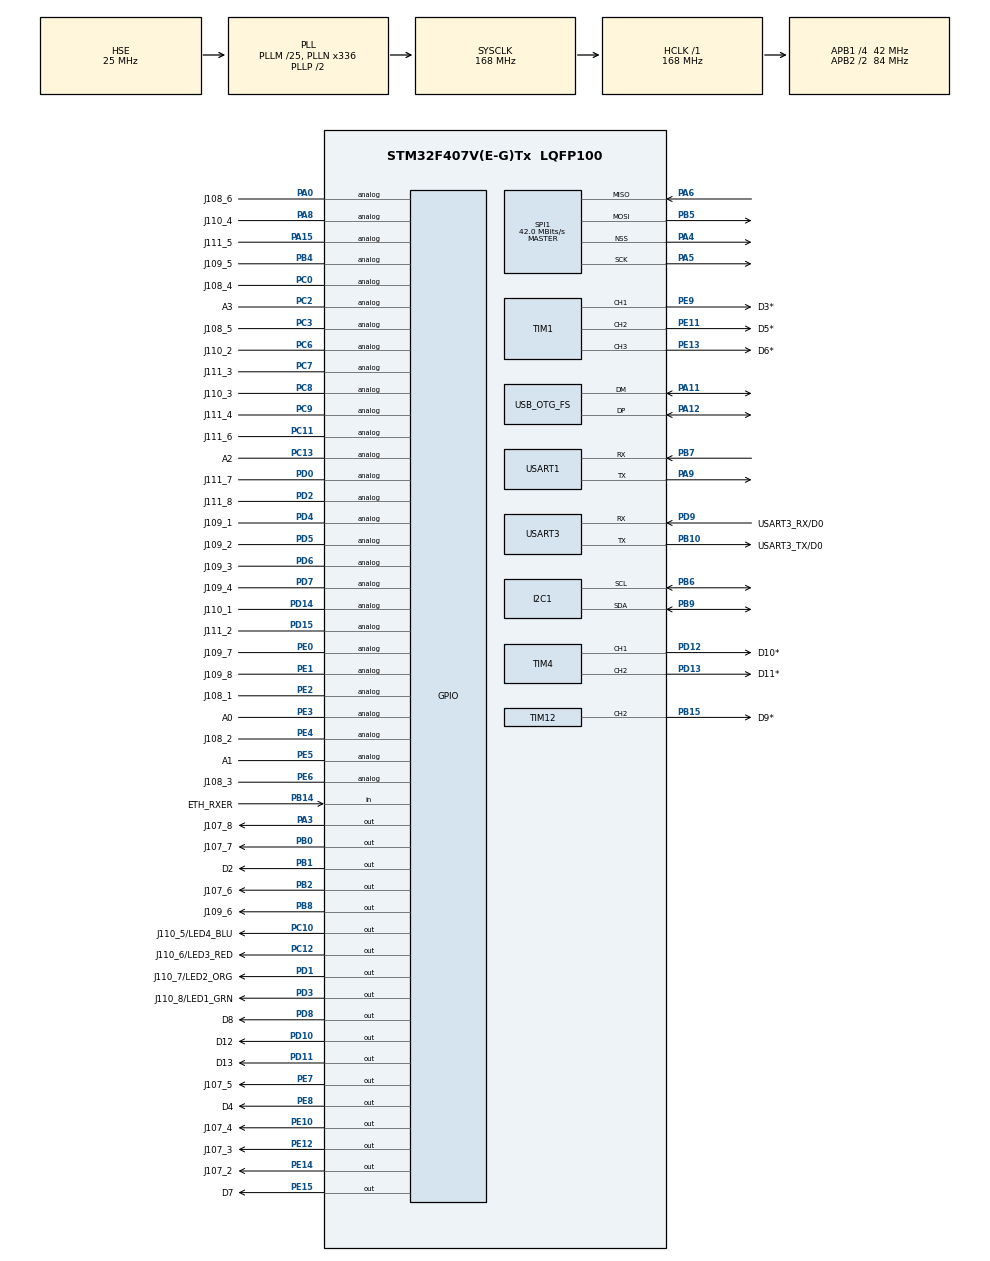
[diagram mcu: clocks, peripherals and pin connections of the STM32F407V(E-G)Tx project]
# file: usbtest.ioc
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Mcu.Family=STM32F4
Mcu.Name=STM32F407V(E-G)Tx
Mcu.Package=LQFP100
NVIC.OTG_FS_IRQn=true\:0\:0\:false\:false\:true\:false\:true\:true
NVIC.PriorityGroup=NVIC_PRIORITYGROUP_4
PA0-WKUP.GPIO_Label=J108_6
PA0-WKUP.Signal=GPIO_Analog
PA11.Mode=Device_Only
PA11.Signal=USB_OTG_FS_DM
PA12.Mode=Device_Only
PA12.Signal=USB_OTG_FS_DP
PA13.Mode=Trace_Asynchronous_SW
PA13.Signal=SYS_JTMS-SWDIO
PA14.Mode=Trace_Asynchronous_SW
PA14.Signal=SYS_JTCK-SWCLK
PA15.GPIO_Label=J111_5
PA15.Signal=GPIO_Analog
PA3.GPIO_Label=J107_8
PA3.Signal=GPIO_Output
PA4.Mode=NSS_Signal_Hard_Output
PA4.Signal=SPI1_NSS
PA5.Mode=Full_Duplex_Master
PA5.Signal=SPI1_SCK
PA6.Mode=Full_Duplex_Master
PA6.Signal=SPI1_MISO
PA8.GPIO_Label=J110_4
PA8.Signal=GPIO_Analog
PA9.Mode=Asynchronous
PA9.Signal=USART1_TX
PB0.GPIO_Label=J107_7
PB0.Signal=GPIO_Output
PB1.GPIO_Label=D2
PB1.Signal=GPIO_Output
PB10.GPIO_Label=USART3_TX/D0
PB10.Mode=Asynchronous
PB10.Signal=USART3_TX
PB14.GPIO_Label=ETH_RXER
PB14.Signal=GPIO_Input
PB15.GPIO_Label=D9*
PB15.Signal=S_TIM12_CH2
PB2.GPIO_Label=J107_6
PB2.Signal=GPIO_Output
PB3.Mode=Trace_Asynchronous_SW
PB3.Signal=SYS_JTDO-SWO
PB4.GPIO_Label=J109_5
PB4.Signal=GPIO_Analog
PB5.Mode=Full_Duplex_Master
PB5.Signal=SPI1_MOSI
PB6.Mode=I2C
PB6.Signal=I2C1_SCL
PB7.Mode=Asynchronous
PB7.Signal=USART1_RX
PB8.GPIO_Label=J109_6
PB8.Signal=GPIO_Output
PB9.Mode=I2C
PB9.Signal=I2C1_SDA
PC0.GPIO_Label=J108_4
PC0.Signal=GPIO_Analog
PC10.GPIO_Label=J110_5/LED4_BLU
PC10.Signal=GPIO_Output
PC11.GPIO_Label=J111_6
PC11.Signal=GPIO_Analog
PC12.GPIO_Label=J110_6/LED3_RED
PC12.Signal=GPIO_Output
PC13-ANTI_TAMP.GPIO_Label=A2
PC13-ANTI_TAMP.Signal=GPIO_Analog
PC14-OSC32_IN.Mode=LSE-External-Oscillator
PC14-OSC32_IN.Signal=RCC_OSC32_IN
PC15-OSC32_OUT.Mode=LSE-External-Oscillator
PC15-OSC32_OUT.Signal=RCC_OSC32_OUT
PC2.GPIO_Label=A3
PC2.Signal=GPIO_Analog
PC3.GPIO_Label=J108_5
PC3.Signal=GPIO_Analog
PC6.GPIO_Label=J110_2
PC6.Signal=GPIO_Analog
PC7.GPIO_Label=J111_3
PC7.Signal=GPIO_Analog
PC8.GPIO_Label=J110_3
PC8.Signal=GPIO_Analog
PC9.GPIO_Label=J111_4
PC9.Signal=GPIO_Analog
PD0.GPIO_Label=J111_7
PD0.Signal=GPIO_Analog
PD1.GPIO_Label=J110_7/LED2_ORG
PD1.Signal=GPIO_Output
PD10.GPIO_Label=D12
PD10.Signal=GPIO_Output
PD11.GPIO_Label=D13
PD11.Signal=GPIO_Output
PD12.GPIO_Label=D10*
PD12.Signal=S_TIM4_CH1
PD13.GPIO_Label=D11*
PD13.Signal=S_TIM4_CH2
PD14.GPIO_Label=J110_1
PD14.Signal=GPIO_Analog
PD15.GPIO_Label=J111_2
PD15.Signal=GPIO_Analog
PD2.GPIO_Label=J111_8
PD2.Signal=GPIO_Analog
PD3.GPIO_Label=J110_8/LED1_GRN
PD3.Signal=GPIO_Output
PD4.GPIO_Label=J109_1
PD4.Signal=GPIO_Analog
PD5.GPIO_Label=J109_2
PD5.Signal=GPIO_Analog
PD6.GPIO_Label=J109_3
PD6.Signal=GPIO_Analog
PD7.GPIO_Label=J109_4
PD7.Signal=GPIO_Analog
PD8.GPIO_Label=D8
PD8.Signal=GPIO_Output
PD9.GPIO_Label=USART3_RX/D0
PD9.Mode=Asynchronous
PD9.Signal=USART3_RX
PE0.GPIO_Label=J109_7
PE0.Signal=GPIO_Analog
PE1.GPIO_Label=J109_8
PE1.Signal=GPIO_Analog
PE10.GPIO_Label=J107_4
PE10.Signal=GPIO_Output
PE11.GPIO_Label=D5*
PE11.Signal=S_TIM1_CH2
PE12.GPIO_Label=J107_3
PE12.Signal=GPIO_Output
PE13.GPIO_Label=D6*
PE13.Signal=S_TIM1_CH3
PE14.GPIO_Label=J107_2
PE14.Signal=GPIO_Output
PE15.GPIO_Label=D7
PE15.Signal=GPIO_Output
PE2.GPIO_Label=J108_1
PE2.Signal=GPIO_Analog
PE3.GPIO_Label=A0
PE3.Signal=GPIO_Analog
PE4.GPIO_Label=J108_2
PE4.Signal=GPIO_Analog
PE5.GPIO_Label=A1
PE5.Signal=GPIO_Analog
PE6.GPIO_Label=J108_3
PE6.Signal=GPIO_Analog
PE7.GPIO_Label=J107_5
PE7.Signal=GPIO_Output
PE8.GPIO_Label=D4
PE8.Signal=GPIO_Output
PE9.GPIO_Label=D3*
PE9.Signal=S_TIM1_CH1
PH0-OSC_IN.Mode=HSE-External-Oscillator
PH0-OSC_IN.Signal=RCC_OSC_IN
PH1-OSC_OUT.Mode=HSE-External-Oscillator
PH1-OSC_OUT.Signal=RCC_OSC_OUT
ProjectManager.HeapSize=0x200
ProjectManager.StackSize=0x400
ProjectManager.TargetToolchain=STM32CubeIDE
RCC.48MHZClocksFreq_Value=48000000
RCC.AHBFreq_Value=168000000
RCC.APB1CLKDivider=RCC_HCLK_DIV4
RCC.APB1Freq_Value=42000000
RCC.APB1TimFreq_Value=84000000
RCC.APB2CLKDivider=RCC_HCLK_DIV2
RCC.APB2Freq_Value=84000000
RCC.APB2TimFreq_Value=168000000
RCC.CortexFreq_Value=168000000
RCC.HCLKFreq_Value=168000000
RCC.HSE_VALUE=25000000
RCC.HSI_VALUE=16000000
RCC.PLLM=25
RCC.PLLN=336
RCC.PLLQ=7
RCC.RCC_RTC_Clock_Source=RCC_RTCCLKSOURCE_LSE
RCC.RCC_RTC_Clock_SourceVirtual=RCC_RTCCLKSOURCE_LSE
RCC.SYSCLKFreq_VALUE=168000000
RCC.SYSCLKSource=RCC_SYSCLKSOURCE_PLLCLK
RCC.VCOOutputFreq_Value=336000000
SH.S_TIM12_CH2.0=TIM12_CH2,PWM Generation2 CH2
SH.S_TIM1_CH1.0=TIM1_CH1,PWM Generation1 CH1
SH.S_TIM1_CH2.0=TIM1_CH2,PWM Generation2 CH2
SH.S_TIM1_CH3.0=TIM1_CH3,PWM Generation3 CH3
SH.S_TIM4_CH1.0=TIM4_CH1,PWM Generation1 CH1
SH.S_TIM4_CH2.0=TIM4_CH2,PWM Generation2 CH2
SPI1.CalculateBaudRate=42.0 MBits/s
SPI1.Direction=SPI_DIRECTION_2LINES
SPI1.Mode=SPI_MODE_MASTER
SPI1.VirtualNSS=VM_NSSHARD
SPI1.VirtualType=VM_MASTER
TIM1.Channel-PWM\ Generation1\ CH1=TIM_CHANNEL_1
TIM1.Channel-PWM\ Generation2\ CH2=TIM_CHANNEL_2
TIM1.Channel-PWM\ Generation3\ CH3=TIM_CHANNEL_3
TIM12.Channel-PWM\ Generation2\ CH2=TIM_CHANNEL_2
TIM4.Channel-PWM\ Generation1\ CH1=TIM_CHANNEL_1
TIM4.Channel-PWM\ Generation2\ CH2=TIM_CHANNEL_2
USART1.VirtualMode=VM_ASYNC
USART3.VirtualMode=VM_ASYNC
USB_DEVICE.CLASS_NAME_FS=CDC
USB_DEVICE.VirtualMode-CDC_FS=Cdc
USB_DEVICE.VirtualModeFS=Cdc_FS
USB_OTG_FS.VirtualMode=Device_Only
VP_RTC_VS_RTC_Activate.Mode=RTC_Enabled
VP_TIM1_VS_ClockSourceINT.Mode=Internal
VP_TIM4_VS_ClockSourceINT.Mode=Internal
VP_USB_DEVICE_VS_USB_DEVICE_CDC_FS.Mode=CDC_FS
board=custom

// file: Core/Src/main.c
/* USER CODE BEGIN Header */
/**
  ******************************************************************************
  * @file           : main.c
  * @brief          : Main program body
  ******************************************************************************
  * @attention
  *
  * Copyright (c) 2023 STMicroelectronics.
  * All rights reserved.
  *
  * This software is licensed under terms that can be found in the LICENSE file
  * in the root directory of this software component.
  * If no LICENSE file comes with this software, it is provided AS-IS.
  *
  ******************************************************************************
  */
/* USER CODE END Header */
#include "main.h"
#include "i2c.h"
#include "rtc.h"
#include "spi.h"
#include "tim.h"
#include "usart.h"
#include "usb_device.h"
#include "gpio.h"

/* USER CODE BEGIN Includes */
#include "usbd_cdc_if.h"
/* USER CODE END Includes */

void SystemClock_Config(void);

int main(void)
{
  /* USER CODE BEGIN 1 */
  DBG=Debugger_create(0);
  /* USER CODE END 1 */

  /* MCU Configuration--------------------------------------------------------*/

  /* Reset of all peripherals, Initializes the Flash interface and the Systick. */
  HAL_Init();

  /* Configure the system clock */
  SystemClock_Config();

  /* Initialize all configured peripherals */
  MX_GPIO_Init();
  MX_RTC_Init();
  MX_SPI1_Init();
  MX_USART1_UART_Init();
  MX_I2C1_Init();
  MX_TIM1_Init();
  MX_TIM4_Init();
  MX_TIM12_Init();
  MX_USART3_UART_Init();
  MX_USB_DEVICE_Init();
  /* USER CODE BEGIN 2 */
    uint32_t tick1 = 0;
    uint32_t tick2 = 0;
    uint32_t counter = 0;
    int8_t counterDirection = 50;

    int8_t ledDirection = 1;
    HAL_TIM_PWM_Start(&htim1, TIM_CHANNEL_1);
    Debugger_log(DBG, "Hello World.\n");
    char buffer[100];
    CDC_Transmit_FS("Hello, World!\n", 15);
  /* USER CODE END 2 */

  /* Infinite loop */
  /* USER CODE BEGIN WHILE */
  while (1)
  {
      if(HAL_GetTick() - tick2 >= 500) {
          tick2=HAL_GetTick();

          if(ledPattern == 5) {
              ledPattern=10;
          } else {
              ledPattern=5;
          }

          HAL_GPIO_WritePin(J110_8_LED1_GRN_GPIO_Port, J110_8_LED1_GRN_Pin, (ledPattern & 1) ? GPIO_PIN_RESET : GPIO_PIN_SET);
          HAL_GPIO_WritePin(J110_7_LED2_ORG_GPIO_Port, J110_7_LED2_ORG_Pin, (ledPattern & 2) ? GPIO_PIN_RESET : GPIO_PIN_SET);
          HAL_GPIO_WritePin(J110_6_LED3_RED_GPIO_Port, J110_6_LED3_RED_Pin, (ledPattern & 4) ? GPIO_PIN_RESET : GPIO_PIN_SET);
          HAL_GPIO_WritePin(J110_5_LED4_BLU_GPIO_Port, J110_5_LED4_BLU_Pin, (ledPattern & 8) ? GPIO_PIN_RESET : GPIO_PIN_SET);
          Debugger_log(DBG, "ledPattern=%lu\n", ledPattern);
          snprintf(buffer, sizeof(buffer), "ledPattern=%lu\n", ledPattern);
          CDC_Transmit_FS(buffer, strlen(buffer));
      }

      /* USER CODE END WHILE */

  }
}

void SystemClock_Config(void)
{
  RCC_OscInitTypeDef RCC_OscInitStruct = {0};
  RCC_ClkInitTypeDef RCC_ClkInitStruct = {0};

  /** Configure the main internal regulator output voltage
  */
  __HAL_RCC_PWR_CLK_ENABLE();
  __HAL_PWR_VOLTAGESCALING_CONFIG(PWR_REGULATOR_VOLTAGE_SCALE1);

  /** Initializes the RCC Oscillators according to the specified parameters
  * in the RCC_OscInitTypeDef structure.
  */
  RCC_OscInitStruct.OscillatorType = RCC_OSCILLATORTYPE_HSE|RCC_OSCILLATORTYPE_LSE;
  RCC_OscInitStruct.HSEState = RCC_HSE_ON;
  RCC_OscInitStruct.LSEState = RCC_LSE_ON;
  RCC_OscInitStruct.PLL.PLLState = RCC_PLL_ON;
  RCC_OscInitStruct.PLL.PLLSource = RCC_PLLSOURCE_HSE;
  RCC_OscInitStruct.PLL.PLLM = 25;
  RCC_OscInitStruct.PLL.PLLN = 336;
  RCC_OscInitStruct.PLL.PLLP = RCC_PLLP_DIV2;
  RCC_OscInitStruct.PLL.PLLQ = 7;
  if (HAL_RCC_OscConfig(&RCC_OscInitStruct) != HAL_OK)
  {
    Error_Handler();
  }

  /** Initializes the CPU, AHB and APB buses clocks
  */
  RCC_ClkInitStruct.ClockType = RCC_CLOCKTYPE_HCLK|RCC_CLOCKTYPE_SYSCLK
                              |RCC_CLOCKTYPE_PCLK1|RCC_CLOCKTYPE_PCLK2;
  RCC_ClkInitStruct.SYSCLKSource = RCC_SYSCLKSOURCE_PLLCLK;
  RCC_ClkInitStruct.AHBCLKDivider = RCC_SYSCLK_DIV1;
  RCC_ClkInitStruct.APB1CLKDivider = RCC_HCLK_DIV4;
  RCC_ClkInitStruct.APB2CLKDivider = RCC_HCLK_DIV2;

  if (HAL_RCC_ClockConfig(&RCC_ClkInitStruct, FLASH_LATENCY_5) != HAL_OK)
  {
    Error_Handler();
  }
}

void Error_Handler(void)
{
  __disable_irq();
  while (1)
  {
  }
}
